# f28004x_analog_subsys_regs register map
Vendor: Texas Instruments
Peripheral module from a debugger description file (folder C2000).
Address unit: 16 bits
Registers are 16-bit, read-write, no defined reset value unless marked. A register's access mark holds for its fields unless they carry their own. Offsets are as the file gives them; lines under a group give offsets from that group; [hi:lo] are bit positions; {n}, {i} and the like mark numbered series; 'fields as' and 'values as' point back to an identical list; <NAME> marks a mode.

## ANALOG_SUBSYS_REGS — ANALOG SUBSYS Registers
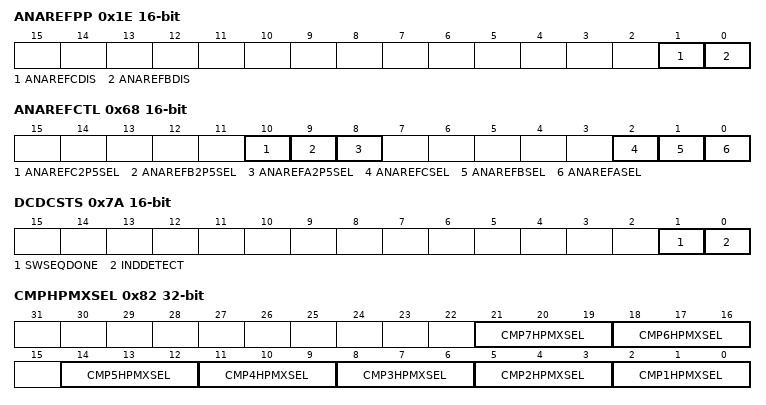
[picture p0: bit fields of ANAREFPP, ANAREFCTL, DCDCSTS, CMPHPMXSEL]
0x1E ANAREFPP — ADC Analog Reference Peripheral Properties register
  [1] ANAREFCDIS — Disable ANAREFC
  [0] ANAREFBDIS — Disable ANAREFB
0x60 TSNSCTL — Temperature Sensor Control Register
  [0] ENABLE — Temperature Sensor Enable
0x68 ANAREFCTL — Analog Reference Control Register
  [10] ANAREFC2P5SEL — Analog Reference B Select
  [9] ANAREFB2P5SEL — Analog Reference B Select
  [8] ANAREFA2P5SEL — Analog Reference A Select
  [2] ANAREFCSEL — Analog Reference C Select
  [1] ANAREFBSEL — Analog Reference B Select
  [0] ANAREFASEL — Analog Reference A Select
0x70 VMONCTL — Voltage Monitor Control Register
  [8] BORLVMONDIS — Disable BORL(ow) feature on VDDIO
0x78 DCDCCTL 32-bit — DC-DC control register.
  [0] DCDCEN — DCDC Enable
0x7A DCDCSTS access per field — DC-DC status register.
  [1] SWSEQDONE ro — Switch sequence to DC-DC done.
  [0] INDDETECT rw — Inductor Detected
0x82 CMPHPMXSEL 32-bit — Bits to select one of the many sources on CopmHP inputs. Refer to Pimux diagram for details.
  [21:19] CMP7HPMXSEL — CMP7HPMXSEL bits
  [18:16] CMP6HPMXSEL — CMP6HPMXSEL bits
  [3n-1:3n-3] CMP{n}HPMXSEL (n=1..5) — CMP{n}HPMXSEL bits
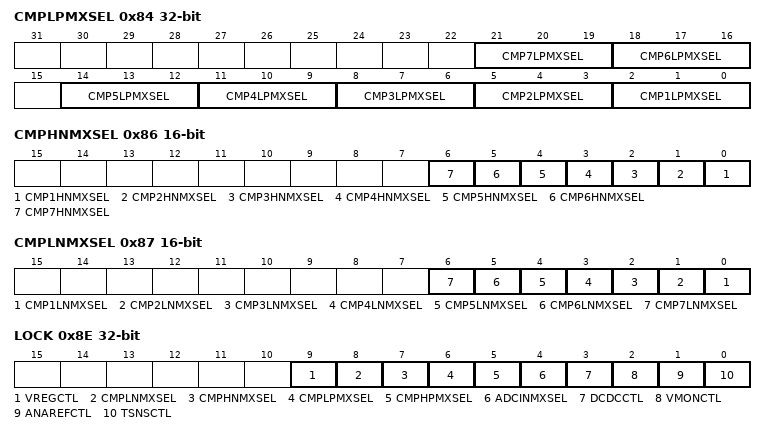
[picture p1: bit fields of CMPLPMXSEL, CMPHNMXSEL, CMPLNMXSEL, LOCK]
0x84 CMPLPMXSEL 32-bit — Bits to select one of the many sources on CopmLP inputs. Refer to Pimux diagram for details.
  [21:19] CMP7LPMXSEL — CMP7LPMXSEL bits
  [18:16] CMP6LPMXSEL — CMP6LPMXSEL bits
  [3n-1:3n-3] CMP{n}LPMXSEL (n=1..5) — CMP{n}LPMXSEL bits
0x86 CMPHNMXSEL — Bits to select one of the many sources on CopmHN inputs. Refer to Pimux diagram for details.
  [n-1] CMP{n}HNMXSEL (n=1..7) — CMP{n}HNMXSEL bits
0x87 CMPLNMXSEL — Bits to select one of the many sources on CopmLN inputs. Refer to Pimux diagram for details.
  [n-1] CMP{n}LNMXSEL (n=1..7) — CMP{n}LNMXSEL bits
0x8E LOCK 32-bit
  [9] VREGCTL — VREGCTL Register lock bit
  [8] CMPLNMXSEL — CMPLNMXSEL Register lock bit
  [7] CMPHNMXSEL — CMPHNMXSEL Register lock bit
  [6] CMPLPMXSEL — CMPLPMXSEL Register lock bit
  [5] CMPHPMXSEL — CMPHPMXSEL Register lock bit
  [4] ADCINMXSEL — ADCINMXSEL Register lock bit
  [3] DCDCCTL — DCDCCTL Register lock bit
  [2] VMONCTL — VMONCTL Register lock bit
  [1] ANAREFCTL — ANAREFCTL Register lock bit
  [0] TSNSCTL — TSNSCTL Register lock bit
